# NUC1311AE_v1 register map
File version: 1.0
Registers are 32-bit, read-write, reset 0x0 unless marked. A register's access mark holds for its fields unless they carry their own. Offsets are from the block's base; [hi:lo] are bit positions; {n}, {i} and the like mark numbered series; 'fields as' and 'values as' point back to an identical list.

## BPWM0 — BPWM Register Map
Base 0x40044000
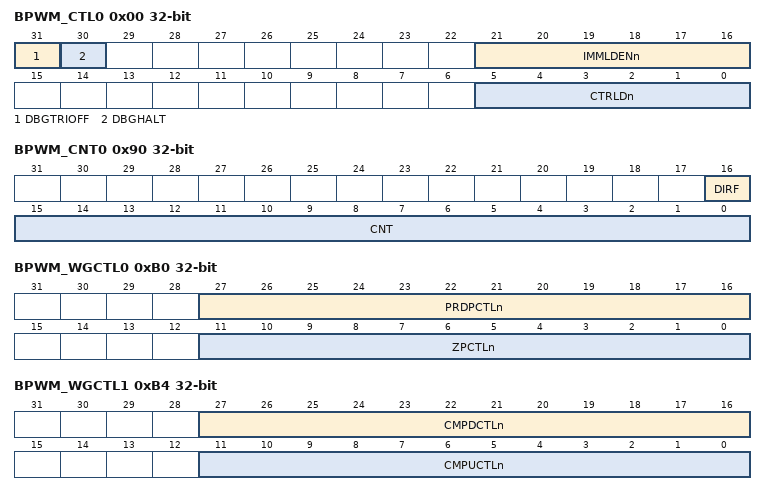
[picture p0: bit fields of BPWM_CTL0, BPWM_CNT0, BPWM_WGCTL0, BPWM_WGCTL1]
0x00 BPWM_CTL0 — BPWM Control Register 0
  [31] DBGTRIOFF — ICE Debug Mode Acknowledge Disable (Write Protect). BPWM pin will keep output no matter ICE debug mode acknowledged or not. Note: This register is write protected. Refer to SYS_REGLCTL register.
    0=ICE debug mode acknowledgement effects BPWM output; 1=ICE debug mode acknowledgement disabled
  [30] DBGHALT — ICE Debug Mode Counter Halt (Write Protect). If counter halt is enabled, BPWM all counters will keep current value until exit ICE debug mode. Note: This register is write protected. Refer to SYS_REGLCTL register.
    0=ICE debug mode counter halt disable; 1=ICE debug mode counter halt enable
  [21:16] IMMLDENn — Immediately Load Enable. Each bit n controls the corresponding BPWM channel n. Note: If IMMLDENn is enabled, WINLDENn and CTRLDn will be invalid.
    0=PERIOD will load to PBUF at the end point of each period. CMPDAT will load to CMPBUF at the end point or center point of each period by setting CTRLD bit; 1=PERIOD/CMPDAT will load to PBUF and CMPBUF immediately when software update PERIOD/CMPDAT
  [5:0] CTRLDn — Center Re-Load. Each bit n controls the corresponding BPWM channel n. In up-down counter type, PERIOD will load to PBUF at the end point of each period. CMPDAT will load to CMPBUF at the center point of a period.
0x04 BPWM_CTL1 — BPWM Control Register 1
  [1:0] CNTTYPE0 — BPWM Counter Behavior Type 0. Each bit n controls corresponding BPWM channel n.
    0=Up counter type (supports in capture mode); 1=Down count type (supports in capture mode); 2=Up-down counter type
0x10 BPWM_CLKSRC — BPWM Clock Source Register
  [2:0] ECLKSRC0 — BPWM_CH01 External Clock Source Select
    0=BPWMx_CLK, x denotes 0 or 1; {v}=TIMER{v-1} overflow (v=1..4)
0x14 BPWM_CLKPSC — BPWM Clock Pre-scale Register
  [11:0] CLKPSC — BPWM Counter Clock Pre-Scale. The clock of BPWM counter is decided by clock prescaler. Each BPWM pair share one BPWM counter clock prescaler. The clock of BPWM counter is divided by (CLKPSC+ 1).
0x20 BPWM_CNTEN — BPWM Counter Enable Register
  [0] CNTEN0 — BPWM Counter Enable 0
    0=BPWM Counter and clock prescaler Stop Running; 1=BPWM Counter and clock prescaler Start Running
0x24 BPWM_CNTCLR — BPWM Clear Counter Register
  [0] CNTCLR0 — Clear BPWM Counter Control Bit 0. It is automatically cleared by hardware.
    0=No effect; 1=Clear 16-bit BPWM counter to 0000H
0x30 BPWM_PERIOD
  [15:0] PERIOD — BPWM Period Register. Up-Count mode: In this mode, BPWM counter counts from 0 to PERIOD, and restarts from 0. Down-Count mode: In this mode, BPWM counter counts from PERIOD to 0, and restarts from PERIOD.
{0x50+4i} BPWM_CMPDAT{i} (i=0..5) — BPWM Comparator Register {i}
  [15:0] CMP — BPWM Comparator Register. CMP use to compare with CNT to generate BPWM waveform, interrupt and trigger ADC. In independent mode, BPWM_CMPDAT0~5 denote as 6 independent BPWM_CH0~5 compared point. In complementary mode, BPWM_CMPDAT0, 2, 4 denote as first compared point, and BPWM_CMPDAT1, 3, 5 denote as second compared point for the corresponding 3 complementary pairs BPWM_CH0 and BPWM_CH1, BPWM_CH2 and BPWM_CH3, BPWM_CH4 and BPWM_CH5.
0x90 BPWM_CNT0 ro — BPWM Counter Register 0
  [16] DIRF — BPWM Direction Indicator Flag (Read Only)
    0=Counter is Down count; 1=Counter is UP count
  [15:0] CNT — BPWM Data Register (Read Only). User can monitor CNT to know the current value in 16-bit period counter.
0xB0 BPWM_WGCTL0 — BPWM Generation Register 0
  [27:16] PRDPCTLn — BPWM Period (Center) Point Control. Each bit n controls the corresponding BPWM channel n. BPWM can control output level when BPWM counter count to (PERIODn+1). Note: This bit is center point control when BPWM counter operating in up-down counter type.
    0=Do nothing; 1=BPWM period (center) point output Low; 2=BPWM period (center) point output High; 3=BPWM period (center) point output Toggle
  [11:0] ZPCTLn — BPWM Zero Point Control. Each bit n controls the corresponding BPWM channel n. BPWM can control output level when BPWM counter count to zero.
    0=Do nothing; 1=BPWM zero point output Low; 2=BPWM zero point output High; 3=BPWM zero point output Toggle
0xB4 BPWM_WGCTL1 — BPWM Generation Register 1
  [27:16] CMPDCTLn — BPWM Compare Down Point Control. Each bit n controls the corresponding BPWM channel n. BPWM can control output level when BPWM counter down count to CMPDAT. Note: In complementary mode, CMPDCTL1, 3, 5 use as another CMPDCTL for channel 0, 2, 4.
    0=Do nothing; 1=BPWM compare down point output Low; 2=BPWM compare down point output High; 3=BPWM compare down point output Toggle
  [11:0] CMPUCTLn — BPWM Compare Up Point Control. Each bit n controls the corresponding BPWM channel n. BPWM can control output level when BPWM counter up count to CMPDAT. Note: In complementary mode, CMPUCTL1, 3, 5 use as another CMPUCTL for channel 0, 2, 4.
    0=Do nothing; 1=BPWM compare up point output Low; 2=BPWM compare up point output High; 3=BPWM compare up point output Toggle
0xB8 BPWM_MSKEN — BPWM Mask Enable Register
  [5:0] MSKENn — BPWM Mask Enable Control. Each bit n controls the corresponding BPWM channel n. The BPWM output signal will be masked when this bit is enabled. The corresponding BPWM channel n will output MSKDATn (BPWM_MSK[5:0]) data.
    0=BPWM output signal is non-masked; 1=BPWM output signal is masked and output MSKDATn data
0xBC BPWM_MSK — BPWM Mask Data Register
  [5:0] MSKDATn — BPWM Mask Data Bit. This data bit control the state of BPWMn output pin, if corresponding mask function is enabled. Each bit n controls the corresponding BPWM channel n.
    0=Output logic low to BPWMn; 1=Output logic high to BPWMn
0xD4 BPWM_POLCTL — BPWM Pin Polar Inverse Register
  [5:0] PINVn — BPWM PIN Polar Inverse Control. The register controls polarity state of BPWM output. Each bit n controls the corresponding BPWM channel n.
    0=BPWM output polar inverse Disabled; 1=BPWM output polar inverse Enabled
0xD8 BPWM_POEN — BPWM Output Enable Register
  [5:0] POENn — BPWM Pin Output Enable Control. Each bit n controls the corresponding BPWM channel n.
    0=BPWM pin at tri-state; 1=BPWM pin in output mode
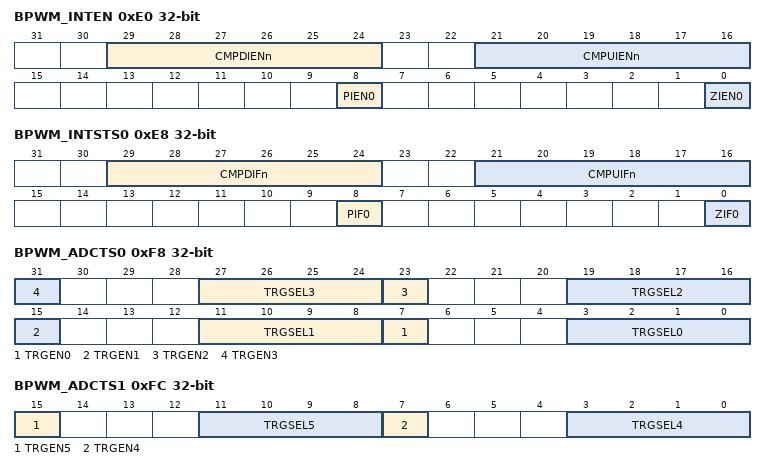
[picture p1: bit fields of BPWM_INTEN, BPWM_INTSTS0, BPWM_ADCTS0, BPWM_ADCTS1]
0xE0 BPWM_INTEN — BPWM Interrupt Enable Register
  [29:24] CMPDIENn — BPWM Compare Down Count Interrupt Enable Control. Each bit n controls the corresponding BPWM channel n. Note: In complementary mode, CMPDIEN1, 3, 5 use as another CMPDIEN for channel 0, 2, 4.
    0=Compare down count interrupt Disabled; 1=Compare down count interrupt Enabled
  [21:16] CMPUIENn — BPWM Compare Up Count Interrupt Enable Control. Each bit n controls the corresponding BPWM channel n. Note: In complementary mode, CMPUIEN1, 3, 5 use as another CMPUIEN for channel 0, 2, 4.
    0=Compare up count interrupt Disabled; 1=Compare up count interrupt Enabled
  [8] PIEN0 — BPWM Period Point Interrupt Enable 0. Note: When up-down counter type period point means center point.
    0=Period point interrupt Disabled; 1=Period point interrupt Enabled
  [0] ZIEN0 — BPWM Zero Point Interrupt Enable 0. Note: Odd channels will read always 0 at complementary mode.
    0=Zero point interrupt Disabled; 1=Zero point interrupt Enabled
0xE8 BPWM_INTSTS0 — BPWM Interrupt Flag Register
  [29:24] CMPDIFn — BPWM Compare Down Count Interrupt Flag. Each bit n controls the corresponding BPWM channel n. Flag is set by hardware when BPWM counter down count and reaches BPWM_CMPDATn, software can clear this bit by writing 1 to it. Note1: If CMPDAT equal to PERIOD, this flag is not working in down counter type selection. Note2: In complementary mode, CMPDIF1, 3, 5 use as another CMPDIF for channel 0, 2, 4.
  [21:16] CMPUIFn — BPWM Compare Up Count Interrupt Flag. Flag is set by hardware when BPWM counter up count and reaches BPWM_CMPDATn, software can clear this bit by writing 1 to it. Each bit n controls the corresponding BPWM channel n. Note1: If CMPDAT equal to PERIOD, this flag is not working in up counter type selection. Note2: In complementary mode, CMPUIF1, 3, 5 use as another CMPUIF for channel 0, 2, 4.
  [8] PIF0 — BPWM Period Point Interrupt Flag 0. This bit is set by hardware when BPWM_CH0 counter reaches BPWM_PERIOD0, software can write 1 to clear this bit to zero.
  [0] ZIF0 — BPWM Zero Point Interrupt Flag 0. This bit is set by hardware when BPWM_CH0 counter reaches zero, software can write 1 to clear this bit to zero.
0xF8 BPWM_ADCTS0 — BPWM Trigger ADC Source Select Register 0
  [8n+7] TRGEN{n} (n=0..3) — BPWM_CH{n} Trigger ADC Enable Control
  [27:24] TRGSEL3 — BPWM_CH3 Trigger ADC Source Select
    0=BPWM_CH2 zero point; 1=BPWM_CH2 period point; 2=BPWM_CH2 zero or period point; 3=BPWM_CH2 up-count CMPDAT point; 4=BPWM_CH2 down-count CMPDAT point; 8=BPWM_CH3 up-count CMPDAT point; 9=BPWM_CH3 down-count CMPDAT point
  [19:16] TRGSEL2 — BPWM_CH2 Trigger ADC Source Select. Others reserved.
    values as TRGSEL3
  [11:8] TRGSEL1 — BPWM_CH1 Trigger ADC Source Select
    0=BPWM_CH0 zero point; 1=BPWM_CH0 period point; 2=BPWM_CH0 zero or period point; 3=BPWM_CH0 up-count CMPDAT point; 4=BPWM_CH0 down-count CMPDAT point; 8=BPWM_CH1 up-count CMPDAT point; 9=BPWM_CH1 down-count CMPDAT point
  [3:0] TRGSEL0 — BPWM_CH0 Trigger ADC Source Select
    values as TRGSEL1
0xFC BPWM_ADCTS1 — BPWM Trigger ADC Source Select Register 1
  [15] TRGEN5 — BPWM_CH5 Trigger ADC Enable Control
  [11:8] TRGSEL5 — BPWM_CH5 Trigger ADC Source Select
    0=BPWM_CH4 zero point; 1=BPWM_CH4 period point; 2=BPWM_CH4 zero or period point; 3=BPWM_CH4 up-count CMPDAT point; 4=BPWM_CH4 down-count CMPDAT point; 8=BPWM_CH5 up-count CMPDAT point; 9=BPWM_CH5 down-count CMPDAT point
  [7] TRGEN4 — BPWM_CH4 Trigger ADC Enable Control
  [3:0] TRGSEL4 — BPWM_CH4 Trigger ADC Source Select
    values as TRGSEL5
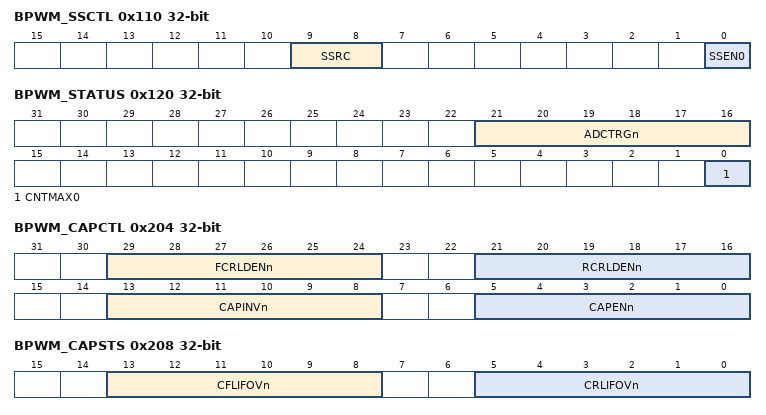
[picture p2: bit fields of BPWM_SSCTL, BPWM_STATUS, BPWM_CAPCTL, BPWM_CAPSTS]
0x110 BPWM_SSCTL — BPWM Synchronous Start Control Register
  [9:8] SSRC — BPWM Synchronous Start Source Select
    0=Synchronous start source come from BPWM0; 1=Synchronous start source come from BPWM1; 2=Synchronous start source come from BPWM0; 3=Synchronous start source come from BPWM1
  [0] SSEN0 — BPWM Synchronous Start Function Enable 0. When synchronous start function is enabled, the BPWM_CH0 counter enable bit (CNTEN0) can be enabled by writing BPWM synchronous start trigger bit (CNTSEN).
    0=BPWM synchronous start function Disabled; 1=BPWM synchronous start function Enabled
0x114 BPWM_SSTRG wo — BPWM Synchronous Start Trigger Register
  [0] CNTSEN — BPWM Counter Synchronous Start Enable (Write Only). PMW counter synchronous enable function is used to make selected BPWM channels (include BPWM0_CHx and BPWM1_CHx) start counting at the same time. Writing this bit to 1 will also set the counter enable bit (CNTENn, n denotes channel 0 to 5) if correlated BPWM channel counter synchronous start function is enabled. Note: This bit only present in BPWM0_BA.
0x120 BPWM_STATUS
  [21:16] ADCTRGn — ADC Start Of Conversion Status. Each bit n controls the corresponding BPWM channel n.
    0=Indicates no ADC start of conversion trigger event has occurred; 1=Indicates an ADC start of conversion trigger event has occurred, software can write 1 to clear this bit
  [0] CNTMAX0 — Time-Base Counter 0 Equal To 0xFFFF Latched Status
    0=Indicates the time-base counter never reached its maximum value 0xFFFF; 1=Indicates the time-base counter reached its maximum value, software can write 1 to clear this bit
0x200 BPWM_CAPINEN — BPWM Capture Input Enable Register
  [5:0] CAPINENn — Capture Input Enable Control. Each bit n controls the corresponding BPWM channel n.
    0=BPWM Channel capture input path Disabled. The input of BPWM channel capture function is always regarded as 0; 1=BPWM Channel capture input path Enabled. The input of BPWM channel capture function comes from correlative multifunction pin
0x204 BPWM_CAPCTL — BPWM Capture Control Register
  [29:24] FCRLDENn — Falling Capture Reload Enable Control. Each bit n controls the corresponding BPWM channel n.
    0=Falling capture reload counter Disabled; 1=Falling capture reload counter Enabled
  [21:16] RCRLDENn — Rising Capture Reload Enable Control. Each bit n controls the corresponding BPWM channel n.
    0=Rising capture reload counter Disabled; 1=Rising capture reload counter Enabled
  [13:8] CAPINVn — Capture Inverter Enable Control. Each bit n controls the corresponding BPWM channel n.
    0=Capture source inverter Disabled; 1=Capture source inverter Enabled. Reverse the input signal from GPIO
  [5:0] CAPENn — Capture Function Enable Control. Each bit n controls the corresponding BPWM channel n.
    0=Capture function Disabled. RCAPDAT/FCAPDAT register will not be updated; 1=Capture function Enabled. Capture latched the BPWM counter value when detected rising or falling edge of input signal and saved to RCAPDAT (Rising latch) and FCAPDAT (Falling latch)
0x208 BPWM_CAPSTS ro — BPWM Capture Status Register
  [13:8] CFLIFOVn — Capture Falling Latch Interrupt Flag Overrun Status (Read Only). This flag indicates if falling latch happened when the corresponding CFLIF is 1. Each bit n controls the corresponding BPWM channel n. Note: This bit will be cleared automatically when user clear corresponding CFLIF.
  [5:0] CRLIFOVn — Capture Rising Latch Interrupt Flag Overrun Status (Read Only). This flag indicates if rising latch happened when the corresponding CRLIF is 1. Each bit n controls the corresponding BPWM channel n. Note: This bit will be cleared automatically when user clear corresponding CRLIF.
{0x20C+8i} BPWM_RCAPDAT{i} ro (i=0..5) — BPWM Rising Capture Data Register {i}
  [15:0] RCAPDAT — BPWM Rising Capture Data Register (Read Only). When rising capture condition happened, the BPWM counter value will be saved in this register.
{0x210+8i} BPWM_FCAPDAT{i} ro (i=0..5) — BPWM Falling Capture Data Register {i}
  [15:0] FCAPDAT — BPWM Falling Capture Data Register (Read Only). When falling capture condition happened, the BPWM counter value will be saved in this register.
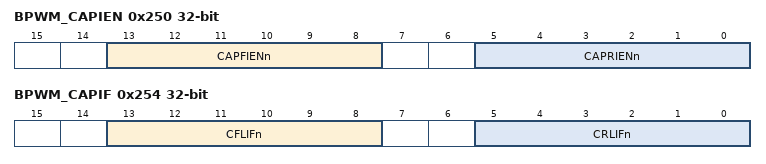
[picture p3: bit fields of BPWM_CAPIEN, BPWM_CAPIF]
0x250 BPWM_CAPIEN — BPWM Capture Interrupt Enable Register
  [13:8] CAPFIENn — BPWM Capture Falling Latch Interrupt Enable Control. Each bit n controls the corresponding BPWM channel n.
    0=Capture falling edge latch interrupt Disabled; 1=Capture falling edge latch interrupt Enabled
  [5:0] CAPRIENn — BPWM Capture Rising Latch Interrupt Enable Control. Each bit n controls the corresponding BPWM channel n.
    0=Capture rising edge latch interrupt Disabled; 1=Capture rising edge latch interrupt Enabled
0x254 BPWM_CAPIF — BPWM Capture Interrupt Flag Register
  [13:8] CFLIFn — BPWM Capture Falling Latch Interrupt Flag. This bit is writing 1 to clear. Each bit n controls the corresponding BPWM channel n.
    0=No capture falling latch condition happened; 1=Capture falling latch condition happened, this flag will be set to high
  [5:0] CRLIFn — BPWM Capture Rising Latch Interrupt Flag. This bit is writing 1 to clear. Each bit n controls the corresponding BPWM channel n.
    0=No capture rising latch condition happened; 1=Capture rising latch condition happened, this flag will be set to high
0x304 BPWM_PBUF ro — BPWM PERIOD Buffer
  [15:0] PBUF — BPWM Period Register Buffer (Read Only). Used as PERIOD active register.
{0x31C+4i} BPWM_CMPBUF{i} ro (i=0..5) — BPWM CMPDAT{i} Buffer
  [15:0] CMPBUF — BPWM Comparator Register Buffer (Read Only). Used as CMP active register.

## BPWM1 — BPWM Register Map
Base 0x40144000
Registers as BPWM0; these are added or differ:
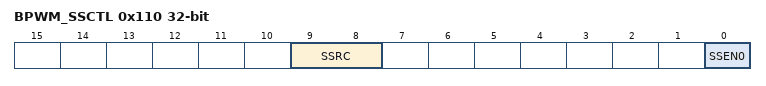
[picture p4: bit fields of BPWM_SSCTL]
0x110 BPWM_SSCTL — BPWM Synchronous Start Control Register
  fields as BPWM0.BPWM_SSCTL
0x114 BPWM_SSTRG wo — BPWM Synchronous Start Trigger Register
  fields as BPWM0.BPWM_SSTRG
